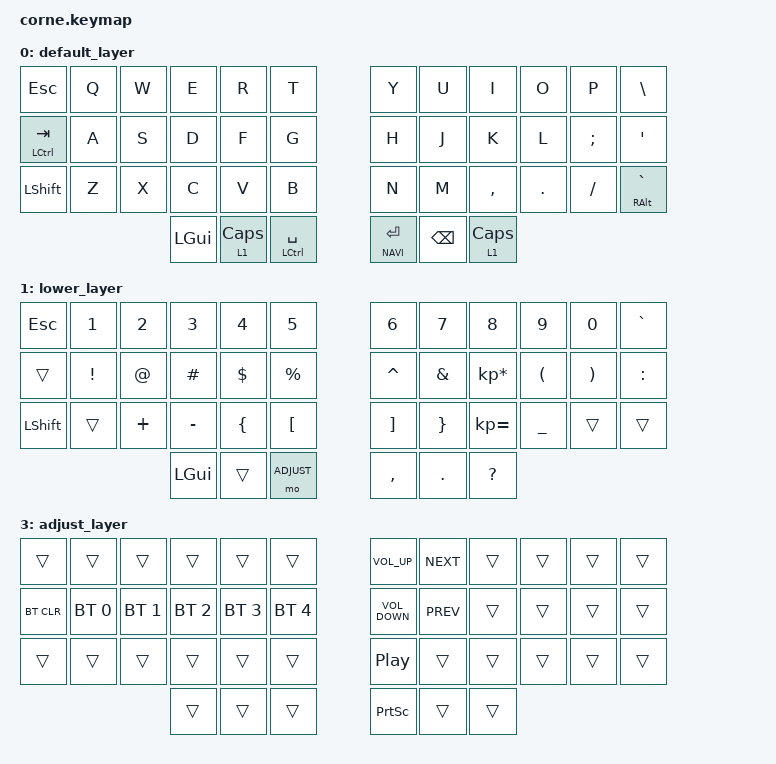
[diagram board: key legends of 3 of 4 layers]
/*
 * Copyright (c) 2020 The ZMK Contributors
 *
 * SPDX-License-Identifier: MIT
 * To use home rows - &hm LSHFT F
 */

#include <behaviors.dtsi>
#include <dt-bindings/zmk/keys.h>
#include <dt-bindings/zmk/bt.h>
#include <dt-bindings/zmk/outputs.h>

#define QWERTY 0
#define NUMB 1
#define NAVI 2
#define ADJUST 3

/ {

    behaviors {
        hm: homerow_mods {
        compatible = "zmk,behavior-hold-tap";
        label = "HOMEROW_MODS";
        #binding-cells = <2>;
        tapping-term-ms = <150>;
        quick_tap_ms = <0>;
        flavor = "tap-preferred";
        bindings = <&kp>, <&kp>;
        };
    };

        keymap {
                compatible = "zmk,keymap";

                default_layer {
// .--------------------------------------------------------------.       .-----------------------------------------------------------.
// |   ESC        |    Q    |    W   |   E    |    R    |    T    |       |   Y   |    U    |    I    |    O    |     P    |    \     |
// |--------------+---------+--------+--------+---------+---------|       |-------+---------+---------+---------+----------+----------|
// |   CTRL/Tab   |    A    |    S   |   D    |    F    |    G    |       |   H   |    J    |    K    |    L    |     ;    |     '    |
// |--------------+---------+--------+--------+---------+---------|       |-------+---------+---------+---------+----------+----------|
// |   SHFT       |    Z    |    X   |   C    |    V    |    B    |       |   N   |    M    |    ,    |    .    |     /    | ` | ALT  |
// '---------------------------------+--------+---------+---------+       |-------+---------+---------+-------------------------------'
//                                   |  GUI   |   MO1   |   SPC   |       |  ENT  |   BKSP  |  CAPS   |
//                                   '--------+---------+---------'       '-------+---------+---------'
                        bindings = <
   &kp ESC        &kp Q   &kp W  &kp E      &kp R        &kp T            &kp Y  &kp U           &kp I        &kp O     &kp P      &kp BACKSLASH
   &mt LCTRL TAB  &kp A   &kp S  &kp D      &kp F        &kp G            &kp H  &kp J           &kp K        &kp L     &kp SEMI   &kp SQT
   &kp LSHFT      &kp Z   &kp X  &kp C      &kp V        &kp B            &kp N  &kp M           &kp COMMA    &kp DOT   &kp FSLH   &mt RALT GRAVE
                                 &kp LGUI   &lt 1 CAPS   &mt LCTRL SPACE  &lt NAVI RET           &kp BSPC     &lt 1 CAPS
                        >;
                };

                lower_layer {
// .--------------------------------------------------------------.       .-----------------------------------------------------------.
// |   ESC        |    1    |    2   |   3    |    4    |    5    |       |   6   |    7    |    8    |    9    |     0    |    `     |
// |--------------+---------+--------+--------+---------+---------|       |-------+---------+---------+---------+----------+----------|
// |              |    !    |    @   |   #    |    $    |    %    |       |   ^   |    &    |    *    |    (    |     )    |     :    |
// |--------------+---------+--------+--------+---------+---------|       |-------+---------+---------+---------+----------+----------|
// |   SHFT       |         |    +   |   -    |    {    |    [    |       |   ]   |    }    |    =    |    _    |          |          |
// '---------------------------------+--------+---------+---------+       |-------+---------+---------+-------------------------------'
//                                   |  GUI   |         |   MO3   |       |   ,   |    .    |   ?     |
//                                   '--------+---------+---------'       '-------+---------+---------'
                        bindings = <
   &kp ESC    &kp N1       &kp N2            &kp N3             &kp N4               &kp N5            &kp N6                   &kp N7                     &kp N8                 &kp N9                   &kp N0     &kp GRAVE
   &trans     &kp EXCL     &kp AT            &kp HASH           &kp DLLR             &kp PRCNT         &kp CARET                &kp AMPS                   &kp KP_MULTIPLY        &kp LPAR                 &kp RPAR   &kp COLON
   &kp LSHFT  &trans       &kp PLUS          &kp MINUS          &kp LEFT_BRACE       &kp LEFT_BRACKET  &kp RIGHT_BRACKET        &kp RIGHT_BRACE            &kp KP_EQUAL           &kp UNDERSCORE           &trans     &trans
                                             &kp LGUI           &trans               &mo ADJUST        &kp COMMA                &kp DOT                    &kp QMARK
                        >;
                };

                raise_layer {
// .----------------------------------------------------------------.       .-----------------------------------------------------------------.
// |       F1       |   F2  |   F3   |   F4   |    F5    |    F6    |       |   F7    |    F8    |    F9   |   F10   |    F11   |     F12     |
// |----------------+-------+--------+--------+----------+----------|       |---------+----------+---------+---------+----------+-------------|
// |                |       |  LEFT  |  DOWN  |   RIGHT  |   END    |       |  LEFT    |   DOWN  |    UP   |  RIGHT  |          |             |
// |----------------+-------+--------+--------+----------+----------|       |---------+----------+---------+---------+----------+-------------|
// |     OUT_TOG    |       |        |        |CTRL+LEFT |CTRL+RIGHT|       |CTRL+LEFT|CTRL+RIGHT|         |         |          |   OUT_TOG   |
// '---------------------------------+--------+----------+----------+       |---------+----------+---------+----------------------------------'
//                                   |  GUI   |   MO3    |          |       |         |          |         |
//                                   '--------+----------+----------'       '---------+----------+---------'

                        bindings = <
   &kp F1          &kp F2     &kp F3         &kp F4            &kp F5                &kp F6                  &kp F7               &kp F8                  &kp F9             &kp F10            &kp F11      &kp F12
   &trans          &trans     &trans         &kp &trans        &kp &trans            &kp END                 &kp LEFT_ARROW       &kp DOWN_ARROW          &kp UP_ARROW       &kp RIGHT_ARROW    &kp END      &trans
   &trans          &trans     &trans         &trans            &kp LC(LEFT_ARROW)    &kp LC(RIGHT_ARROW)     &kp LC(LEFT_ARROW)   &kp LC(RIGHT_ARROW)     &trans             &trans             &trans       &kp RALT
                                             &kp LGUI          &mo ADJUST            &trans                  &trans               &trans                  &trans
                        >;
                };

                adjust_layer {
// .--------------------------------------------------------.       .--------------------------------------------------------------.
// |         |        |        |        |         |         |       |  VOL+  |        |         |         |          |             |
// |---------+--------+--------+--------+---------+---------|       |--------+--------+---------+---------+----------+-------------|
// |  BTCLR  |  BT1   |  BT2   |  BT3   |  BT4    |  BT5    |       |  VOL-  |        |         |         |          |             |
// |---------+--------+--------+--------+---------+---------|       |--------+--------+---------+---------+----------+-------------|
// |         |        |        |        |         |         |       |        |        |         |         |          |             |
// '---------------------------+--------+---------+---------+       |--------+--------+---------+----------------------------------'
//                             |        |         |         |       |        |        |         |
//                             '--------+---------+---------'       '--------+--------+---------'

                        bindings = <
   &trans      &trans        &trans        &trans        &trans        &trans            &kp C_VOLUME_UP    &kp C_NEXT &trans &trans &trans &trans
   &bt BT_CLR  &bt BT_SEL 0  &bt BT_SEL 1  &bt BT_SEL 2  &bt BT_SEL 3  &bt BT_SEL 4      &kp C_VOLUME_DOWN  &kp C_PREV &trans &trans &trans &trans
   &trans      &trans        &trans        &trans        &trans        &trans            &kp C_PP           &trans     &trans &trans &trans &trans
                                           &trans        &trans        &trans            &kp PSCRN          &trans     &trans
                        >;
                };
        };
};

